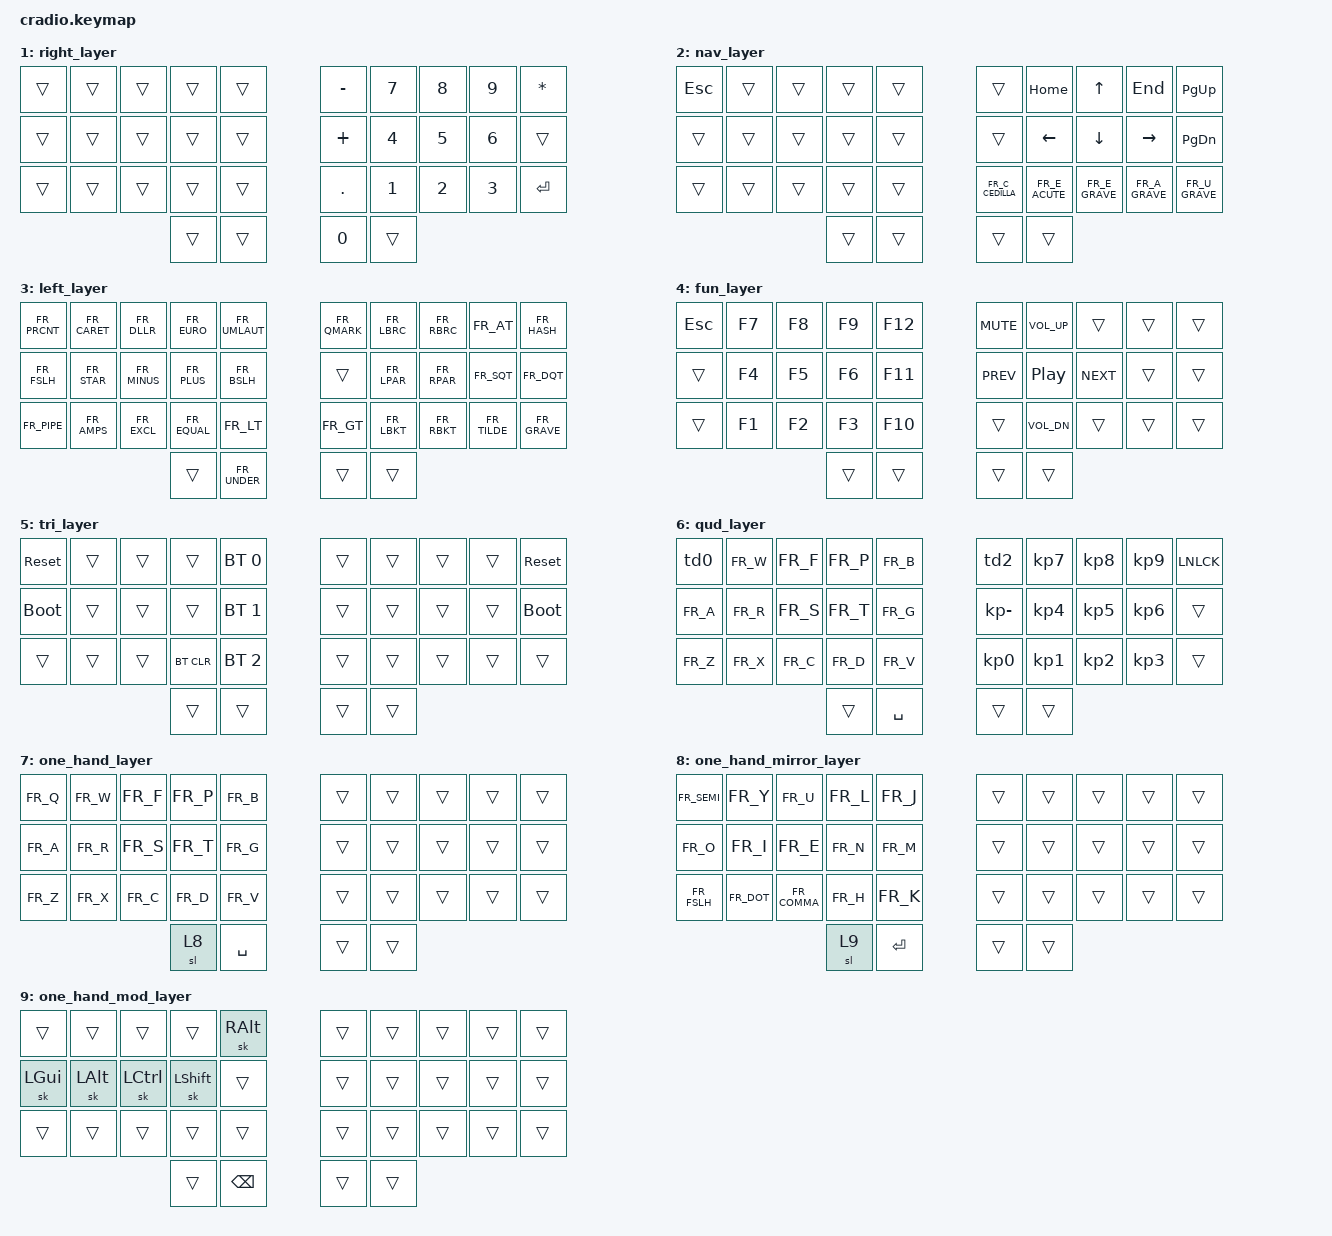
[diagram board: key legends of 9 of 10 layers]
// Copyright (c) 2022 The ZMK Contributors
// SPDX-License-Identifier: MIT

#include <behaviors.dtsi>
#include <dt-bindings/zmk/keys.h>
#include <dt-bindings/zmk/bt.h>
#include "keys_fr_canadian_standard.h"

// Home row mods macro
#define HRML(k1,k2,k3,k4) &ht LGUI k1  &ht LALT k2  &ht LCTRL k3  &ht LSHFT k4
#define HRMR(k1,k2,k3,k4) &ht RSHFT k1  &ht LCTRL k2  &ht LALT k3  &ht RGUI k4 // RALT is ALT_GR

/ {
    behaviors {
        ht: hold_tap {
            label = "hold_tap";
            compatible = "zmk,behavior-hold-tap";
            #binding-cells = <2>;
            flavor = "balanced";
            tapping-term-ms = <280>;
            quick-tap-ms = <175>;
            require-prior-idle-ms = <150>;
            global-quick-tap;
            bindings = <&kp>, <&kp>;
        };
        td0: tap_dance_0 {
            compatible = "zmk,behavior-tap-dance";
            label = "TAP_DANCE_0";
            #binding-cells = <0>;
            tapping-term-ms = <200>;
            bindings = <&kp FR_Q>, <&kp ESC>;
        };
        td1: tap_dance_1 {
            compatible = "zmk,behavior-tap-dance";
            label = "TAP_DANCE_1";
            #binding-cells = <0>;
            tapping-term-ms = <200>;
            bindings = <&kp FR_J>, <&tog 6>;
        };
        td2: tap_dance_2 {
            compatible = "zmk,behavior-tap-dance";
            label = "TAP_DANCE_2";
            #binding-cells = <0>;
            tapping-term-ms = <200>;
            bindings = <&kp KP_PLUS>, <&tog 6>;
        };

    };
   combos {
        compatible = "zmk,combos";
        combo_esc {
            timeout-ms = <50>;
            key-positions = <13 16>;
            bindings = <&caps_word>;
        };
        combo_one_hand {
            timeout-ms = <50>;
            key-positions = <0 1 2 3>;
            bindings = <&tog 7>;
        };
    };
    conditional_layers {
        compatible = "zmk,conditional-layers";
        tri_layer {
            if-layers = <2 4>;
            then-layer = <5>;
        };
    };

    keymap {
        compatible = "zmk,keymap";
        default_layer {
            bindings = <
        //╭──────────┬──────────┬──────────┬──────────┬──────────╮   ╭──────────┬──────────┬──────────┬──────────┬──────────╮
        //│  Q       │  W       │  F       │  P       │  B       │   │  J       │  L       │  U       │  Y       │  ;       │
            &td0       &kp FR_W  &kp FR_F    &kp FR_P   &kp FR_B      &td1       &kp FR_L   &kp FR_U   &kp FR_Y   &kp FR_SEMI
        //├──────────┼──────────┼──────────┼──────────┼──────────┤   ├──────────┼──────────┼──────────┼──────────┼──────────┤
        //│  A       │  R       │  S       │  T       │  G       │   │  M       │  N       │  E       │  I       │ O        │
            HRML(FR_A,  FR_R,         FR_S,    FR_T)     &kp FR_G     &kp FR_M  HRMR(FR_N,     FR_E,      FR_I,        FR_O)
        //├──────────┼──────────┼──────────┼──────────┼──────────┤   ├──────────┼──────────┼──────────┼──────────┼──────────┤
        //│  Z       │  X       │  C       │  D       │  V       │   │  K       │  H,       │ , '      │ . "      │ / ?      │
            &kp FR_Z  &kp FR_X     &kp FR_C   &kp FR_D   &kp FR_V      &kp FR_K &kp FR_H  &kp FR_COMMA  &kp FR_DOT  &kp FR_FSLH
        //╰──────────┴──────────┴──────────┼──────────┼──────────┤   ├──────────┼──────────┼──────────┴──────────┴──────────╯
                                            &lt 2 TAB   &lt 1 SPACE     &lt 3 ENTER  &lt 4 BSPC
        //                                 ╰──────────┴──────────╯   ╰──────────┴──────────╯
            >;
        };

        right_layer {
            bindings = <
        //╭──────────┬──────────┬──────────┬──────────┬──────────╮   ╭──────────┬──────────┬──────────┬──────────┬──────────╮
        //│ INSERT   │  1       │  2       │  3       │          │   │ HOME     │ PAGE DN  │ PAGE UP  │ END      │  :       │
            &trans    &trans     &trans     &trans     &trans         &kp MINUS   &kp N7    &kp N8    &kp N9    &kp STAR
        //├──────────┼──────────┼──────────┼──────────┼──────────┤   ├──────────┼──────────┼──────────┼──────────┼──────────┤
        //│ DELETE   │  4       │  5       │  6       │          │   │ LEFT     │ DOWN     │ UP       │ RIGHT    │  ;       │
            &trans    &trans     &trans     &trans     &trans         &kp PLUS   &kp N4    &kp N5     &kp N6    &trans
        //├──────────┼──────────┼──────────┼──────────┼──────────┤   ├──────────┼──────────┼──────────┼──────────┼──────────┤
        //│ CAPS     │  7       │  8       │  9       │  0       │   │          │          │          │          │          │
           &trans     &trans    &trans     &trans     &trans        &kp DOT     &kp N1     &kp N2     &kp N3     &kp ENTER
        //╰──────────┴──────────┴──────────┼──────────┼──────────┤   ├──────────┼──────────┼──────────┴──────────┴──────────╯
                                             &trans     &trans        &kp N0     &trans
        //                                 ╰──────────┴──────────╯   ╰──────────┴──────────╯
            >;
        };
        nav_layer {
            bindings = <
        //╭──────────┬──────────┬──────────┬──────────┬──────────╮   ╭──────────┬──────────┬──────────┬──────────┬──────────╮
        //│          │  [       │  {       │  }       │          │   │  ^       │  (       │  )       │  ]       │  ~       │
            &kp ESC     &trans     &trans     &trans     &trans         &trans     &kp HOME   &kp UP   &kp END   &kp PG_UP
        //├──────────┼──────────┼──────────┼──────────┼──────────┤   ├──────────┼──────────┼──────────┼──────────┼──────────┤
        //│  !       │  @       │  #       │  $       │  %       │   │  *       │  -       │  =       │  \       │  `       │
            &trans    &trans     &trans     &trans     &trans        &trans    &kp LEFT  &kp DOWN  &kp RIGHT   &kp PG_DN
        //├──────────┼──────────┼──────────┼──────────┼──────────┤   ├──────────┼──────────┼──────────┼──────────┼──────────┤
        //│          │          │          │          │          │   │  &       │  _       │  +       │  │       │          │
            &trans     &trans     &trans     &trans     &trans         &kp FR_C_CEDILLA  &kp FR_E_ACUTE  &kp FR_E_GRAVE   &kp FR_A_GRAVE   &kp FR_U_GRAVE
        //╰──────────┴──────────┴──────────┼──────────┼──────────┤   ├──────────┼──────────┼──────────┴──────────┴──────────╯
                                             &trans     &trans         &trans     &trans
        //                                 ╰──────────┴──────────╯   ╰──────────┴──────────╯
            >;
        };
        left_layer {
            bindings = <
        //╭──────────┬──────────┬──────────┬──────────┬──────────╮   ╭──────────┬──────────┬──────────┬──────────┬──────────╮
        //│          │  [       │  {       │  }       │          │   │  ^       │  (       │  )       │  ]       │  ~       │
        &kp FR_PRCNT &kp FR_CARET  &kp FR_DLLR   &kp FR_EURO   &kp FR_UMLAUT         &kp FR_QMARK &kp FR_LBRC   &kp FR_RBRC   &kp FR_AT   &kp FR_HASH
        //├──────────┼──────────┼──────────┼──────────┼──────────┤   ├──────────┼──────────┼──────────┼──────────┼──────────┤
        //│  !       │  @       │  #       │  $       │  %       │   │  *       │  -       │  =       │  \       │  `       │
        &kp FR_FSLH   &kp FR_STAR     &kp FR_MINUS   &kp FR_PLUS   &kp FR_BSLH      &trans  &kp FR_LPAR  &kp FR_RPAR  &kp FR_SQT   &kp FR_DQT
        //├──────────┼──────────┼──────────┼──────────┼──────────┤   ├──────────┼──────────┼──────────┼──────────┼──────────┤
        //│          │          │          │          │          │   │  &       │  _       │  +       │  │       │          │
          &kp FR_PIPE  &kp FR_AMPS  &kp FR_EXCL &kp FR_EQUAL  &kp FR_LT            &kp FR_GT   &kp FR_LBKT  &kp FR_RBKT   &kp FR_TILDE   &kp FR_GRAVE
        //╰──────────┴──────────┴──────────┼──────────┼──────────┤   ├──────────┼──────────┼──────────┴──────────┴──────────╯
                                             &trans     &kp FR_UNDER         &trans     &trans
        //                                 ╰──────────┴──────────╯   ╰──────────┴──────────╯
            >;
        };

        fun_layer {
            bindings = <
        //╭──────────┬──────────┬──────────┬──────────┬──────────╮  ╭──────────┬──────────┬──────────┬──────────┬──────────╮
        //│ INSERT   │  1       │  2       │  3       │          │  │          │          │          │          │          │
            &kp ESC    &kp F7      &kp F8     &kp F9    &kp F12         &kp C_MUTE     &kp C_VOL_UP     &trans     &trans      &trans
        //├──────────┼──────────┼──────────┼──────────┼──────────┤  ├──────────┼──────────┼──────────┼──────────┼──────────┤
        //│ DELETE   │  4       │  5       │  6       │          │  │          │          │          │          │          │
            &trans    &kp F4      &kp F5      &kp F6    &kp F11         &kp C_PREV     &kp C_PP     &kp C_NEXT &trans    &trans
        //├──────────┼──────────┼──────────┼──────────┼──────────┤  ├──────────┼──────────┼──────────┼──────────┼──────────┤
        //│ CAPS     │  7       │  8       │  9       │  0       │  │          │          │          │          │          │
           &trans     &kp F1      &kp F2     &kp F3     &kp F10         &trans     &kp C_VOL_DN     &trans     &trans     &trans
        //╰──────────┴──────────┴──────────┼──────────┼──────────┤  ├──────────┼──────────┼──────────┴──────────┴──────────╯
                                             &trans     &trans        &trans     &trans
        //                                 ╰──────────┴──────────╯  ╰──────────┴──────────╯
            >;
        };

        tri_layer {
            bindings = <
        //╭──────────┬──────────┬──────────┬──────────┬──────────╮   ╭──────────┬──────────┬──────────┬──────────┬──────────╮
        //│ RESET    │          │          │          │PROFILE 0 │   │          │          │          │          │  RESET   │
            &sys_reset     &trans     &trans     &trans    &bt BT_SEL 0    &trans     &trans     &trans     &trans      &sys_reset
        //├──────────┼──────────┼──────────┼──────────┼──────────┤   ├──────────┼──────────┼──────────┼──────────┼──────────┤
        //│BOOTLOADER│          │          │          │PROFILE 1 │   │          │          │          │          │BOOTLOADER│
          &bootloader  &trans     &trans     &trans    &bt BT_SEL 1    &trans     &trans     &trans     &trans    &bootloader
        //├──────────┼──────────┼──────────┼──────────┼──────────┤   ├──────────┼──────────┼──────────┼──────────┼──────────┤
        //│          │          │          │ CLEAR BT │PROFILE 2 │   │          │          │          │          │          │
            &trans     &trans     &trans    &bt BT_CLR &bt BT_SEL 2    &trans     &trans     &trans     &trans     &trans
        //╰──────────┴──────────┴──────────┼──────────┼──────────┤   ├──────────┼──────────┼──────────┴──────────┴──────────╯
                                             &trans     &trans         &trans     &trans
        //                                 ╰──────────┴──────────╯   ╰──────────┴──────────╯
            >;
        };
         qud_layer {
            bindings = <
        //╭──────────┬──────────┬──────────┬──────────┬──────────╮   ╭──────────┬──────────┬──────────┬──────────┬──────────╮
        //│ RESET    │          │          │          │PROFILE 0 │   │          │          │          │          │          │
            &td0       &kp FR_W  &kp FR_F    &kp FR_P   &kp FR_B          &td2     &kp KP_N7     &kp KP_N8     &kp KP_N9      &kp LNLCK
        //├──────────┼──────────┼──────────┼──────────┼──────────┤   ├──────────┼──────────┼──────────┼──────────┼──────────┤
        //│BOOTLOADER│          │          │          │PROFILE 1 │   │          │          │          │          │          │
            &kp FR_A   &kp FR_R   &kp FR_S  &kp FR_T     &kp FR_G          &kp KP_MINUS     &kp KP_N4     &kp KP_N5     &kp KP_N6    &trans
        //├──────────┼──────────┼──────────┼──────────┼──────────┤   ├──────────┼──────────┼──────────┼──────────┼──────────┤
        //│          │          │          │ CLEAR BT │PROFILE 2 │   │          │          │          │          │          │
            &kp FR_Z  &kp FR_X     &kp FR_C   &kp FR_D   &kp FR_V         &kp KP_N0     &kp KP_N1     &kp KP_N2     &kp KP_N3     &trans
        //╰──────────┴──────────┴──────────┼──────────┼──────────┤   ├──────────┼──────────┼──────────┴──────────┴──────────╯
                                             &trans     &kp SPACE         &trans     &trans
        //                                 ╰──────────┴──────────╯   ╰──────────┴──────────╯
            >;
        };

        one_hand_layer {
            bindings = <
        //╭──────────┬──────────┬──────────┬──────────┬──────────╮   ╭──────────┬──────────┬──────────┬──────────┬──────────╮
        //│  Q       │  W       │  F       │  P       │  B       │   │          │          │          │          │          │
            &kp FR_Q   &kp FR_W   &kp FR_F   &kp FR_P   &kp FR_B       &trans     &trans     &trans     &trans     &trans
        //├──────────┼──────────┼──────────┼──────────┼──────────┤   ├──────────┼──────────┼──────────┼──────────┼──────────┤
        //│  A       │  R       │  S       │  T       │  G       │   │          │          │          │          │          │
            &kp FR_A   &kp FR_R   &kp FR_S   &kp FR_T   &kp FR_G       &trans     &trans     &trans     &trans     &trans
        //├──────────┼──────────┼──────────┼──────────┼──────────┤   ├──────────┼──────────┼──────────┼──────────┼──────────┤
        //│  Z       │  X       │  C       │  D       │  V       │   │          │          │          │          │          │
            &kp FR_Z   &kp FR_X   &kp FR_C   &kp FR_D   &kp FR_V       &trans     &trans     &trans     &trans     &trans
        //╰──────────┴──────────┴──────────┼──────────┼──────────┤   ├──────────┼──────────┼──────────┴──────────┴──────────╯
        //                     mirror(one-shot) │  SPACE   │              (unused - right half not reachable)
                                             &sl 8      &kp SPACE      &trans     &trans
        //                                 ╰──────────┴──────────╯   ╰──────────┴──────────╯
            >;
        };

        one_hand_mirror_layer {
            bindings = <
        //╭──────────┬──────────┬──────────┬──────────┬──────────╮   ╭──────────┬──────────┬──────────┬──────────┬──────────╮
        //│  ;       │  Y       │  U       │  L       │  J       │   │          │          │          │          │          │
            &kp FR_SEMI &kp FR_Y &kp FR_U   &kp FR_L   &kp FR_J       &trans     &trans     &trans     &trans     &trans
        //├──────────┼──────────┼──────────┼──────────┼──────────┤   ├──────────┼──────────┼──────────┼──────────┼──────────┤
        //│  O       │  I       │  E       │  N       │  M       │   │          │          │          │          │          │
            &kp FR_O   &kp FR_I   &kp FR_E   &kp FR_N   &kp FR_M       &trans     &trans     &trans     &trans     &trans
        //├──────────┼──────────┼──────────┼──────────┼──────────┤   ├──────────┼──────────┼──────────┼──────────┼──────────┤
        //│  /       │  .       │  ,       │  H       │  K       │   │          │          │          │          │          │
            &kp FR_FSLH &kp FR_DOT &kp FR_COMMA &kp FR_H &kp FR_K     &trans     &trans     &trans     &trans     &trans
        //╰──────────┴──────────┴──────────┼──────────┼──────────┤   ├──────────┼──────────┼──────────┴──────────┴──────────╯
        //                    mods(one-shot,double-tap) │  ENTER   │              (unused - right half not reachable)
                                             &sl 9      &kp ENTER      &trans     &trans
        //                                 ╰──────────┴──────────╯   ╰──────────┴──────────╯
            >;
        };

        one_hand_mod_layer {
            bindings = <
        //╭──────────┬──────────┬──────────┬──────────┬──────────╮   ╭──────────┬──────────┬──────────┬──────────┬──────────╮
        //│          │          │          │          │ ALT GR   │   │          │          │          │          │          │
            &trans     &trans     &trans     &trans     &sk RALT      &trans     &trans     &trans     &trans     &trans
        //├──────────┼──────────┼──────────┼──────────┼──────────┤   ├──────────┼──────────┼──────────┼──────────┼──────────┤
        //│  GUI     │  ALT     │  CTRL    │  SHIFT   │          │   │          │          │          │          │          │
            &sk LGUI   &sk LALT   &sk LCTRL  &sk LSHFT  &trans        &trans     &trans     &trans     &trans     &trans
        //├──────────┼──────────┼──────────┼──────────┼──────────┤   ├──────────┼──────────┼──────────┼──────────┼──────────┤
        //│          │          │          │          │          │   │          │          │          │          │          │
            &trans     &trans     &trans     &trans     &trans        &trans     &trans     &trans     &trans     &trans
        //╰──────────┴──────────┴──────────┼──────────┼──────────┤   ├──────────┼──────────┼──────────┴──────────┴──────────╯
                                             &trans     &kp BSPC      &trans     &trans
        //                                 ╰──────────┴──────────╯   ╰──────────┴──────────╯
            >;
        };
    };
};
